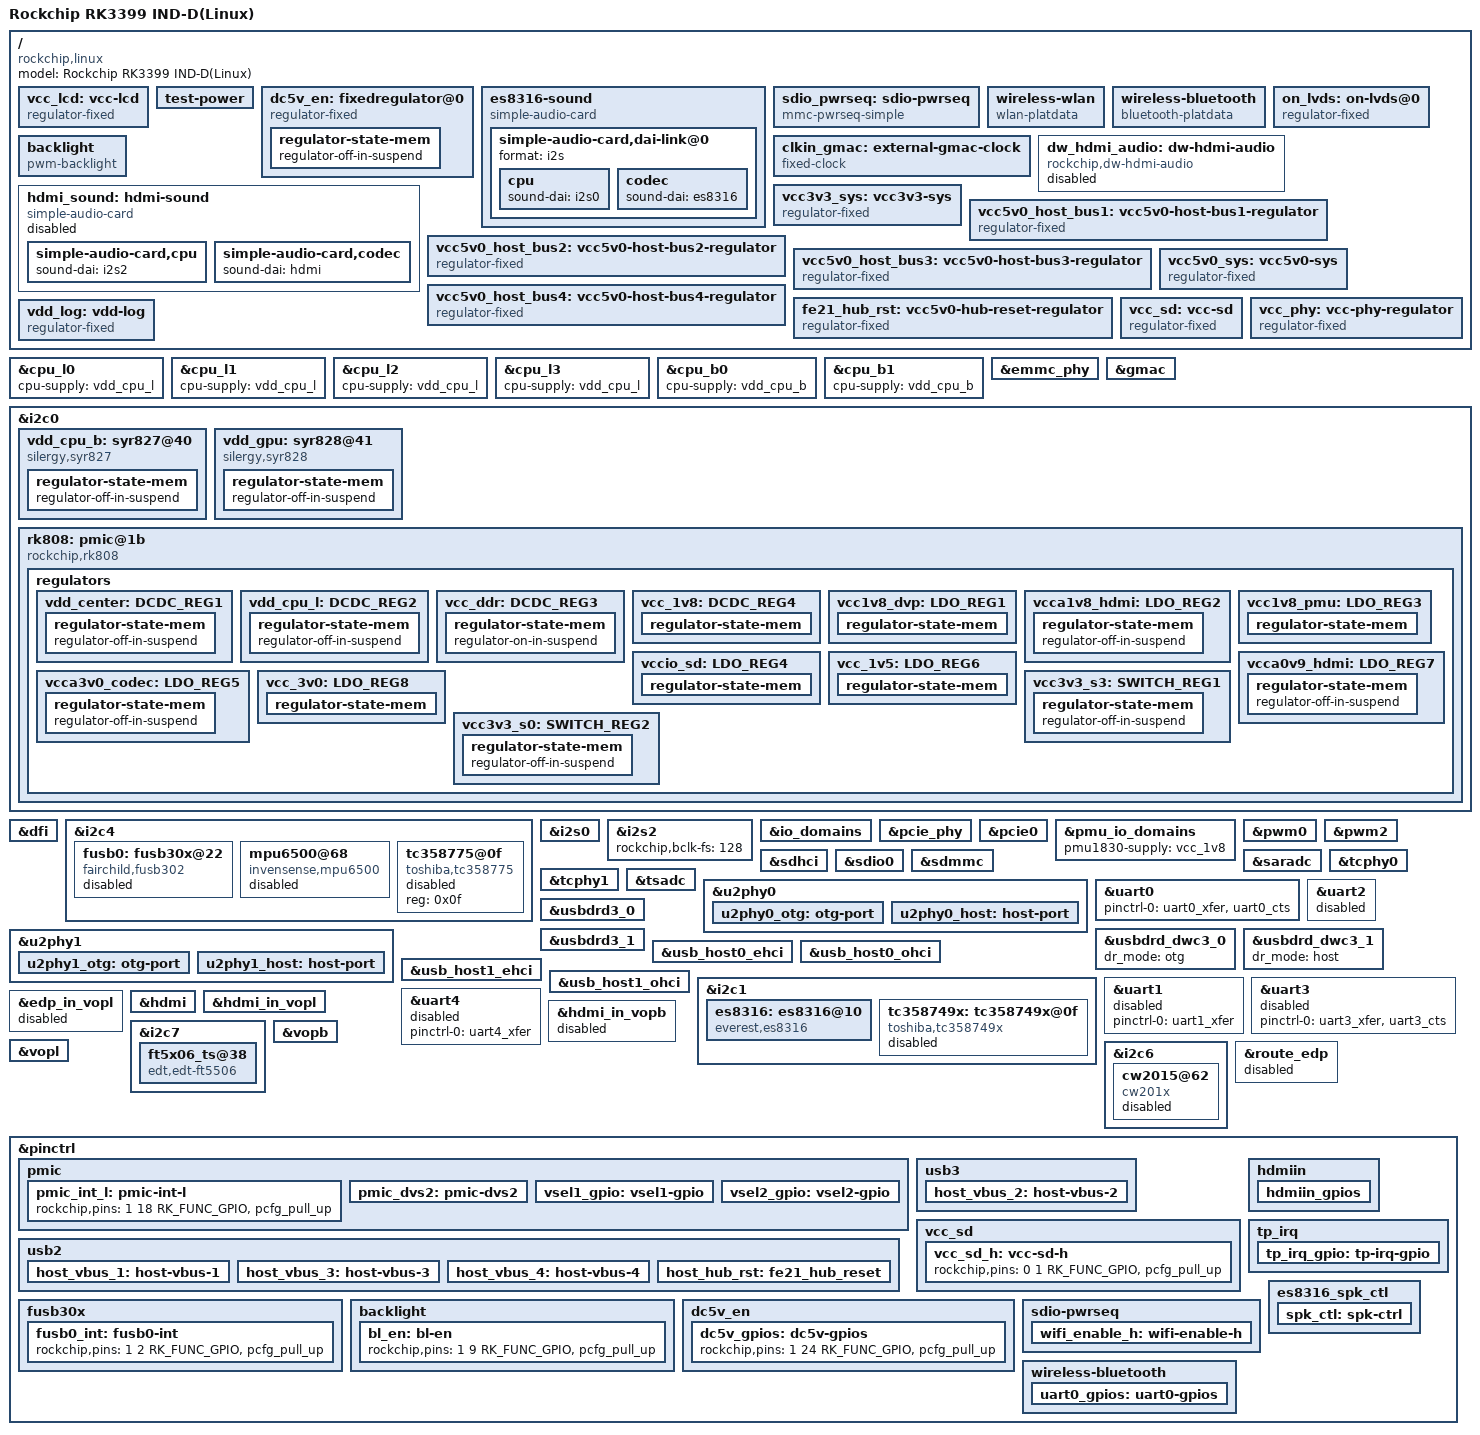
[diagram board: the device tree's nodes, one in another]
/*
 * Copyright (c) 2016 Fuzhou Rockchip Electronics Co., Ltd
 *
 * This file is dual-licensed: you can use it either under the terms
 * of the GPL or the X11 license, at your option. Note that this dual
 * licensing only applies to this file, and not this project as a
 * whole.
 *
 *  a) This file is free software; you can redistribute it and/or
 *     modify it under the terms of the GNU General Public License as
 *     published by the Free Software Foundation; either version 2 of the
 *     License, or (at your option) any later version.
 *
 *     This file is distributed in the hope that it will be useful,
 *     but WITHOUT ANY WARRANTY; without even the implied warranty of
 *     MERCHANTABILITY or FITNESS FOR A PARTICULAR PURPOSE.  See the
 *     GNU General Public License for more details.
 *
 * Or, alternatively,
 *
 *  b) Permission is hereby granted, free of charge, to any person
 *     obtaining a copy of this software and associated documentation
 *     files (the "Software"), to deal in the Software without
 *     restriction, including without limitation the rights to use,
 *     copy, modify, merge, publish, distribute, sublicense, and/or
 *     sell copies of the Software, and to permit persons to whom the
 *     Software is furnished to do so, subject to the following
 *     conditions:
 *
 *     The above copyright notice and this permission notice shall be
 *     included in all copies or substantial portions of the Software.
 *
 *     THE SOFTWARE IS PROVIDED "AS IS", WITHOUT WARRANTY OF ANY KIND,
 *     EXPRESS OR IMPLIED, INCLUDING BUT NOT LIMITED TO THE WARRANTIES
 *     OF MERCHANTABILITY, FITNESS FOR A PARTICULAR PURPOSE AND
 *     NONINFRINGEMENT. IN NO EVENT SHALL THE AUTHORS OR COPYRIGHT
 *     HOLDERS BE LIABLE FOR ANY CLAIM, DAMAGES OR OTHER LIABILITY,
 *     WHETHER IN AN ACTION OF CONTRACT, TORT OR OTHERWISE, ARISING
 *     FROM, OUT OF OR IN CONNECTION WITH THE SOFTWARE OR THE USE OR
 *     OTHER DEALINGS IN THE SOFTWARE.
 */

/dts-v1/;

//#include "rk3399-ind-linux.dtsi"
//#include "rk3399-vop-clk-set.dtsi"
#include "dt-bindings/pwm/pwm.h"
#include "rk3399.dtsi"
//#include "rk3399-opp.dtsi"
#include <dt-bindings/pinctrl/rockchip.h>
#include "rk3399-sdram-lpddr3-4GB-1600.dtsi"
#include "rk3399-u-boot.dtsi"
#include <dt-bindings/input/input.h>
/ {
	model = "Rockchip RK3399 IND-D(Linux)";
	compatible = "rockchip,linux", "rockchip,rk3399-excavator-edp", "rockchip,rk3399";

	vcc_lcd: vcc-lcd {
		compatible = "regulator-fixed";
		regulator-name = "vcc_lcd";
		gpio = <&gpio4 30 GPIO_ACTIVE_HIGH>;
		startup-delay-us = <20000>;
		enable-active-high;
		regulator-min-microvolt = <3300000>;
		regulator-max-microvolt = <3300000>;
		regulator-boot-on;
		vin-supply = <&vcc5v0_sys>;
	};

	test-power {
		status = "okay";
	};

	dc5v_en:fixedregulator@0 {
		compatible = "regulator-fixed";
		regulator-name = "dc5v_en-supply";
		pinctrl-names = "default";
		pinctrl-0=<&dc5v_gpios>;
		regulator-min-microvolt = <1800000>;
        regulator-max-microvolt = <1800000>;
		gpio  = <&gpio1 24 GPIO_ACTIVE_HIGH>;
		enable-active-high;
		regulator-always-on;
		regulator-boot-on;
		enable-at-boot;
		regulator-initial-state = <3>;
		regulator-state-mem{
		regulator-off-in-suspend;
		};
	};
		
	es8316-sound {
		compatible = "simple-audio-card";
		simple-audio-card,format = "i2s";
		simple-audio-card,name = "rockchip,es8316-codec";
		simple-audio-card,mclk-fs = <256>;
		simple-audio-card,widgets =
			"Microphone", "Mic Jack",
			"Headphone", "Headphone Jack";
		simple-audio-card,routing =
			"Mic Jack", "MICBIAS1",
			"IN1P", "Mic Jack",
			"Headphone Jack", "HPOL",
			"Headphone Jack", "HPOR";
		simple-audio-card,dai-link@0 {
			format = "i2s";
			cpu {
				sound-dai = <&i2s0>;
			};

			codec {
				sound-dai = <&es8316>;
			};
		};
	};
	
	sdio_pwrseq: sdio-pwrseq {
		compatible = "mmc-pwrseq-simple";
		clocks = <&rk808 1>;
		clock-names = "ext_clock";
		pinctrl-names = "default";
		pinctrl-0 = <&wifi_enable_h>;

		/*
		 * On the module itself this is one of these (depending
		 * on the actual card populated):
		 * - SDIO_RESET_L_WL_REG_ON
		 * - PDN (power down when low)
		 */
		reset-gpios = <&gpio0 10 GPIO_ACTIVE_LOW>; /* GPIO0_B2 */
	};

	wireless-wlan {
		compatible = "wlan-platdata";
		rockchip,grf = <&grf>;
		wifi_chip_type = "ap6354";
		sdio_vref = <1800>;
		WIFI,host_wake_irq = <&gpio0 3 GPIO_ACTIVE_HIGH>; /* GPIO0_a3 */
		status = "okay";
	};

	wireless-bluetooth {
		compatible = "bluetooth-platdata";
		clocks = <&rk808 1>;
		clock-names = "ext_clock";
		//wifi-bt-power-toggle;
		uart_rts_gpios = <&gpio2 19 GPIO_ACTIVE_LOW>; /* GPIO2_C3 */
		pinctrl-names = "default", "rts_gpio";
		pinctrl-0 = <&uart0_rts>;
		pinctrl-1 = <&uart0_gpios>;
		//BT,power_gpio  = <&gpio3 19 GPIO_ACTIVE_HIGH>; /* GPIOx_xx */
		BT,reset_gpio    = <&gpio0 9 GPIO_ACTIVE_HIGH>; /* GPIO0_B1 */
		BT,wake_gpio     = <&gpio2 27 GPIO_ACTIVE_HIGH>; /* GPIO2_D3 */
		BT,wake_host_irq = <&gpio0 4 GPIO_ACTIVE_HIGH>; /* GPIO0_A4 */
		status = "okay";
	};
	
	on_lvds:on-lvds@0 {
		compatible = "regulator-fixed";
		regulator-name = "on_lvds";
		gpio = <&gpio4 3 GPIO_ACTIVE_HIGH>;
		enable-active-high;
		regulator-min-microvolt = <3300000>;
		regulator-max-microvolt = <3300000>;
		regulator-boot-on;
	};

	backlight: backlight {
		status = "okay";
		compatible = "pwm-backlight";
		power-supply = <&on_lvds>;
		pwms = <&pwm0 0 25000 0>;
		brightness-levels = <
			 70 70  71  71  71  72  72  72
			 73  73  73  74  74  74  75  75
			 75  76  76  76  77  77  77  78
			 78  78  79  79  79  80  80  80
			 81  81  82  82  83  83  84  84
			 85  85  86  86  87  87  88  88
			 89  89  90  90  91  91  92  92
			 93  93  94  94  95  95  96  96
			 97  97  98  98  99  99  100  100
			101  101  102  102  103  103  104  104
			105  105  106  106  107  107  108  108
			109  109  110  110  111  111  112  112
			113  113  114  114 115 115 116 116
			117 117 118 118 119 119 120 121
			122 122 123 124 124 125 126 126
			127 128 128 129 130 131 131 132
			133 133 134 135 136 136 137 138
			138 139 140 141 141 142 143 143
			144 145 146 147 148 149 150 151
			152 153 154 155 156 157 158 159
			160 161 162 163 164 165 166 167
			168 169 170 171 172 173 174 175
			176 177 178 179 180 181 182 183
			184 185 186 187 188 189 190 191
			192 193 194 195 196 197 198 199
			200 201 202 203 204 205 206 207
			208 209 210 211 212 213 214 215
			216 217 218 219 220 221 222 223
			224 225 226 227 228 229 230 231
			232 233 234 235 236 237 238 239
			240 241 242 243 244 245 246 247
			248 249 250 251 252 253 254 255
		>;
		default-brightness-level = <200>;
		pinctrl-names = "default";
		pinctrl-0 = <&bl_en>;
		enable-gpios = <&gpio1 9 GPIO_ACTIVE_LOW>;
		enable-delay-ms = <20>;
	};

	clkin_gmac: external-gmac-clock {
		compatible = "fixed-clock";
		clock-frequency = <125000000>;
		clock-output-names = "clkin_gmac";
		#clock-cells = <0>;
	};

	dw_hdmi_audio: dw-hdmi-audio {
		status = "disabled";
		compatible = "rockchip,dw-hdmi-audio";
		#sound-dai-cells = <0>;
	};

	hdmi_sound: hdmi-sound {
		status = "disabled";
		compatible = "simple-audio-card";
		simple-audio-card,format = "i2s";
		simple-audio-card,mclk-fs = <256>;
		simple-audio-card,name = "rockchip,hdmi";

		simple-audio-card,cpu {
			sound-dai = <&i2s2>;
		};
		simple-audio-card,codec {
			sound-dai = <&hdmi>;
		};
	};

	vcc3v3_sys: vcc3v3-sys {
		compatible = "regulator-fixed";
		regulator-name = "vcc3v3_sys";
		regulator-always-on;
		regulator-boot-on;
		regulator-min-microvolt = <3300000>;
		regulator-max-microvolt = <3300000>;
	};

	vcc5v0_host_bus1: vcc5v0-host-bus1-regulator {
		compatible = "regulator-fixed";
		enable-active-high;
		gpio = <&gpio4 28 GPIO_ACTIVE_HIGH>;
		pinctrl-names = "default";
		pinctrl-0 = <&host_vbus_1>;
		regulator-name = "vcc5v0_host_bus1";
		regulator-always-on;
	};
	
	vcc5v0_host_bus2: vcc5v0-host-bus2-regulator {
		compatible = "regulator-fixed";
		enable-active-high;
		gpio = <&gpio4 4 GPIO_ACTIVE_HIGH>;
		pinctrl-names = "default";
		pinctrl-0 = <&host_vbus_2>;
		regulator-name = "vcc5v0_host_bus2";
		regulator-always-on;
	};
	
	vcc5v0_host_bus3: vcc5v0-host-bus3-regulator {
		compatible = "regulator-fixed";
		enable-active-high;
		gpio = <&gpio4 5 GPIO_ACTIVE_HIGH>;
		pinctrl-names = "default";
		pinctrl-0 = <&host_vbus_3>;
		regulator-name = "vcc5v0_host_bus3";
		regulator-always-on;
	};
	
	vcc5v0_host_bus4: vcc5v0-host-bus4-regulator {
		compatible = "regulator-fixed";
		enable-active-high;
		gpio = <&gpio4 6 GPIO_ACTIVE_HIGH>;
		pinctrl-names = "default";
		pinctrl-0 = <&host_vbus_4>;
		regulator-name = "vcc5v0_host_bus4";
		regulator-always-on;
	};

	fe21_hub_rst: vcc5v0-hub-reset-regulator {
		compatible = "regulator-fixed";
		enable-active-high;
		gpio = <&gpio4 21 GPIO_ACTIVE_HIGH>;
		pinctrl-names = "default";
		pinctrl-0 = <&host_hub_rst>;
		regulator-name = "fe21_hub_rst";
		regulator-always-on;
	};

	vcc5v0_sys: vcc5v0-sys {
		compatible = "regulator-fixed";
		regulator-name = "vcc5v0_sys";
		regulator-always-on;
		regulator-boot-on;
		regulator-min-microvolt = <5000000>;
		regulator-max-microvolt = <5000000>;
	};

	vcc_sd: vcc-sd {
		compatible = "regulator-fixed";
		enable-active-high;
		gpio = <&gpio0 1 GPIO_ACTIVE_HIGH>;
		pinctrl-names = "default";
		pinctrl-0 = <&vcc_sd_h>;
		regulator-name = "vcc_sd";
		regulator-min-microvolt = <3300000>;
		regulator-max-microvolt = <3300000>;
	};

	vcc_phy: vcc-phy-regulator {
		compatible = "regulator-fixed";
		regulator-name = "vcc_phy";
		regulator-always-on;
		regulator-boot-on;
	};

	vdd_log: vdd-log {
		//compatible = "pwm-regulator";
		compatible = "regulator-fixed";
		//pwms = <&pwm2 0 25000 1>;
		regulator-name = "vdd_log";
		regulator-min-microvolt = <800000>;
		regulator-max-microvolt = <1400000>;
		regulator-always-on;
		regulator-boot-on;

		/* for rockchip boot on
		rockchip,pwm_id= <2>;
		rockchip,pwm_voltage = <900000>; */
	};
};

&cpu_l0 {
	cpu-supply = <&vdd_cpu_l>;
};

&cpu_l1 {
	cpu-supply = <&vdd_cpu_l>;
};

&cpu_l2 {
	cpu-supply = <&vdd_cpu_l>;
};

&cpu_l3 {
	cpu-supply = <&vdd_cpu_l>;
};

&cpu_b0 {
	cpu-supply = <&vdd_cpu_b>;
};

&cpu_b1 {
	cpu-supply = <&vdd_cpu_b>;
};

&emmc_phy {
	status = "okay";
};

&gmac {
	phy-supply = <&vcc_phy>;
	phy-mode = "rgmii";
	clock_in_out = "input";
	snps,reset-gpio = <&gpio3 15 GPIO_ACTIVE_LOW>;
	snps,reset-active-low;
	snps,reset-delays-us = <0 10000 50000>;
	assigned-clocks = <&cru SCLK_RMII_SRC>;
	assigned-clock-parents = <&clkin_gmac>;
	pinctrl-names = "default";
	pinctrl-0 = <&rgmii_pins>;
	tx_delay = <0x28>;
	rx_delay = <0x11>;
	status = "okay";
};

&i2c0 {
	status = "okay";
	i2c-scl-rising-time-ns = <168>;
	i2c-scl-falling-time-ns = <4>;
	clock-frequency = <400000>;

	vdd_cpu_b: syr827@40 {
		compatible = "silergy,syr827";
		reg = <0x40>;
		vin-supply = <&vcc5v0_sys>;
		regulator-compatible = "fan53555-reg";
		pinctrl-names = "default";
		pinctrl-0 = <&vsel1_gpio>;
		vsel-gpios = <&gpio1 17 GPIO_ACTIVE_HIGH>;
		regulator-name = "vdd_cpu_b";
		regulator-min-microvolt = <712500>;
		regulator-max-microvolt = <1500000>;
		regulator-ramp-delay = <1000>;
		fcs,suspend-voltage-selector = <1>;
		regulator-always-on;
		regulator-boot-on;
		regulator-initial-state = <3>;
			regulator-state-mem {
			regulator-off-in-suspend;
		};
	};

	vdd_gpu: syr828@41 {
		compatible = "silergy,syr828";
		reg = <0x41>;
		vin-supply = <&vcc5v0_sys>;
		regulator-compatible = "fan53555-reg";
		pinctrl-names = "default";
		pinctrl-0 = <&vsel2_gpio>;
		vsel-gpios = <&gpio1 14 GPIO_ACTIVE_HIGH>;
		regulator-name = "vdd_gpu";
		regulator-min-microvolt = <712500>;
		regulator-max-microvolt = <1500000>;
		regulator-ramp-delay = <1000>;
		fcs,suspend-voltage-selector = <1>;
		regulator-always-on;
		regulator-boot-on;
		regulator-initial-state = <3>;
			regulator-state-mem {
			regulator-off-in-suspend;
		};
	};

	rk808: pmic@1b {
		compatible = "rockchip,rk808";
		reg = <0x1b>;
		interrupt-parent = <&gpio1>;
		interrupts = <21 IRQ_TYPE_LEVEL_LOW>;
		pinctrl-names = "default";
		pinctrl-0 = <&pmic_int_l &pmic_dvs2>;
		rockchip,system-power-controller;
		wakeup-source;
		#clock-cells = <1>;
		clock-output-names = "xin32k", "rk808-clkout2";

		vcc1-supply = <&vcc3v3_sys>;
		vcc2-supply = <&vcc3v3_sys>;
		vcc3-supply = <&vcc3v3_sys>;
		vcc4-supply = <&vcc3v3_sys>;
		vcc6-supply = <&vcc3v3_sys>;
		vcc7-supply = <&vcc3v3_sys>;
		vcc8-supply = <&vcc3v3_sys>;
		vcc9-supply = <&vcc3v3_sys>;
		vcc10-supply = <&vcc3v3_sys>;
		vcc11-supply = <&vcc3v3_sys>;
		vcc12-supply = <&vcc3v3_sys>;
		vddio-supply = <&vcc_3v0>;

		regulators {
			vdd_center: DCDC_REG1 {
				regulator-always-on;
				regulator-boot-on;
				regulator-min-microvolt = <750000>;
				regulator-max-microvolt = <1350000>;
				regulator-ramp-delay = <6001>;
				regulator-name = "vdd_center";
				regulator-state-mem {
					regulator-off-in-suspend;
				};
			};

			vdd_cpu_l: DCDC_REG2 {
				regulator-always-on;
				regulator-boot-on;
				regulator-min-microvolt = <750000>;
				regulator-max-microvolt = <1350000>;
				regulator-ramp-delay = <6001>;
				regulator-name = "vdd_cpu_l";
				regulator-state-mem {
					regulator-off-in-suspend;
				};
			};

			vcc_ddr: DCDC_REG3 {
				regulator-always-on;
				regulator-boot-on;
				regulator-name = "vcc_ddr";
				regulator-state-mem {
					regulator-on-in-suspend;
				};
			};

			vcc_1v8: DCDC_REG4 {
				regulator-always-on;
				regulator-boot-on;
				regulator-min-microvolt = <1800000>;
				regulator-max-microvolt = <1800000>;
				regulator-name = "vcc_1v8";
				regulator-state-mem {
					regulator-on-in-suspend;
					regulator-suspend-microvolt = <1800000>;
				};
			};

			vcc1v8_dvp: LDO_REG1 {
				regulator-always-on;
				regulator-boot-on;
				regulator-min-microvolt = <1800000>;
				regulator-max-microvolt = <1800000>;
				regulator-name = "vcc1v8_dvp";
				regulator-state-mem {
					regulator-on-in-suspend;
					regulator-suspend-microvolt = <1800000>;
				};
			};

			vcca1v8_hdmi: LDO_REG2 {
				regulator-always-on;
				regulator-boot-on;
				regulator-min-microvolt = <1800000>;
				regulator-max-microvolt = <1800000>;
				regulator-name = "vcca1v8_hdmi";
				regulator-state-mem {
					regulator-off-in-suspend;
				};
			};

			vcc1v8_pmu: LDO_REG3 {
				regulator-always-on;
				regulator-boot-on;
				regulator-min-microvolt = <1800000>;
				regulator-max-microvolt = <1800000>;
				regulator-name = "vcc1v8_pmu";
				regulator-state-mem {
					regulator-on-in-suspend;
					regulator-suspend-microvolt = <1800000>;
				};
			};

			vccio_sd: LDO_REG4 {
				regulator-always-on;
				regulator-boot-on;
				regulator-min-microvolt = <1800000>;
				regulator-max-microvolt = <3000000>;
				regulator-name = "vccio_sd";
				regulator-state-mem {
					regulator-on-in-suspend;
					regulator-suspend-microvolt = <3000000>;
				};
			};

			vcca3v0_codec: LDO_REG5 {
				regulator-always-on;
				regulator-boot-on;
				regulator-min-microvolt = <3000000>;
				regulator-max-microvolt = <3000000>;
				regulator-name = "vcca3v0_codec";
				regulator-state-mem {
					regulator-off-in-suspend;
				};
			};

			vcc_1v5: LDO_REG6 {
				regulator-always-on;
				regulator-boot-on;
				regulator-min-microvolt = <1500000>;
				regulator-max-microvolt = <1500000>;
				regulator-name = "vcc_1v5";
				regulator-state-mem {
					regulator-on-in-suspend;
					regulator-suspend-microvolt = <1500000>;
				};
			};

			vcca0v9_hdmi: LDO_REG7 {
				regulator-always-on;
				regulator-boot-on;
				regulator-min-microvolt = <900000>;
				regulator-max-microvolt = <900000>;
				regulator-name = "vcca0v9_hdmi";
				regulator-state-mem {
					regulator-off-in-suspend;
				};
			};

			vcc_3v0: LDO_REG8 {
				regulator-always-on;
				regulator-boot-on;
				regulator-min-microvolt = <3000000>;
				regulator-max-microvolt = <3000000>;
				regulator-name = "vcc_3v0";
				regulator-state-mem {
					regulator-on-in-suspend;
					regulator-suspend-microvolt = <3000000>;
				};
			};

			vcc3v3_s3: SWITCH_REG1 {
				regulator-always-on;
				regulator-boot-on;
				regulator-name = "vcc3v3_s3";
				regulator-state-mem {
					regulator-off-in-suspend;
				};
			};

			vcc3v3_s0: SWITCH_REG2 {
				regulator-always-on;
				regulator-boot-on;
				regulator-name = "vcc3v3_s0";
				regulator-state-mem {
					regulator-off-in-suspend;
				};
			};
		};
	};
	
};

&dfi {
	status = "okay";
};

&i2c4 {
	status = "okay";
	i2c-scl-rising-time-ns = <475>;
	i2c-scl-falling-time-ns = <26>;

	fusb0: fusb30x@22 {
		compatible = "fairchild,fusb302";
		reg = <0x22>;
		pinctrl-names = "default";
		pinctrl-0 = <&fusb0_int>;
		int-n-gpios = <&gpio1 2 GPIO_ACTIVE_HIGH>;
		vbus-5v-gpios = <&gpio2 0 GPIO_ACTIVE_HIGH>;
		status = "disabled";
	};
};

&i2s0 {
	status = "okay";
	rockchip,i2s-broken-burst-len;
	rockchip,playback-channels = <8>;
	rockchip,capture-channels = <8>;
	#sound-dai-cells = <0>;
};

&i2s2 {
	#sound-dai-cells = <0>;
	status = "okay";
};

&io_domains {
	status = "okay";

	//bt656-supply = <&vcc_1v8>;		/* bt656_gpio2ab_ms APIO2 not connect*/
	audio-supply = <&vcc1v8_dvp>;	/*VLDO1 */  /* audio_gpio3d4a_ms d:APIO5 1.8V RK808 Buck4*/
	sdmmc-supply = <&vccio_sd>;		/* sdmmc_gpio4b_ms  d:SDMMC0 3.0V RK808 VLDO4*/
	gpio1830-supply = <&vcc_3v0>;		/* gpio1833_gpio4cd_ms d:APIO4 3.0V RK808 VLDO8*/ 
    	bt656-supply = <&vcc_1v8>;	/*APIO3 1.8V RK808 Buck4 */
};

&pcie_phy {
	status = "okay";
};

&pcie0 {
	ep-gpios = <&gpio2 RK_PA4 GPIO_ACTIVE_HIGH>;
	num-lanes = <4>;
	pinctrl-names = "default";
	pinctrl-0 = <&pcie_clkreqn>;
	status = "okay";
};

&pmu_io_domains {
	status = "okay";
	pmu1830-supply = <&vcc_1v8>; /* datasheet pmu1830_gpio1abcd  d:PMUIO2 1.8V RK808 Buck4 */
};

&pwm0 {
	status = "okay";
};

&pwm2 {
	status = "okay";
};

&sdhci {
	bus-width = <8>;
	mmc-hs400-1_8v;
	supports-emmc;
	non-removable;
	keep-power-in-suspend;
	mmc-hs400-enhanced-strobe;
	status = "okay";
};

&sdio0 {
	clock-frequency = <50000000>;
	clock-freq-min-max = <200000 50000000>;
	supports-sdio;
	bus-width = <4>;
	disable-wp;
	cap-sd-highspeed;
	cap-sdio-irq;
	keep-power-in-suspend;
	mmc-pwrseq = <&sdio_pwrseq>;
	non-removable;
	num-slots = <1>;
	pinctrl-names = "default";
	pinctrl-0 = <&sdio0_bus4 &sdio0_cmd &sdio0_clk>;
	sd-uhs-sdr104;
	status = "okay";
};

&sdmmc {
	clock-frequency = <150000000>;
	clock-freq-min-max = <100000 150000000>;
	supports-sd;
	bus-width = <4>;
	cap-mmc-highspeed;
	cap-sd-highspeed;
	disable-wp;
	num-slots = <1>;
	//sd-uhs-sdr104;
	vmmc-supply = <&vcc_sd>;
	vqmmc-supply = <&vccio_sd>;
	pinctrl-names = "default";
	pinctrl-0 = <&sdmmc_clk &sdmmc_cmd &sdmmc_cd &sdmmc_bus4>;
	status = "okay";
};

&saradc {
	status = "okay";
};

&tcphy0 {
	/*extcon = <&fusb0>;*/
	/*extcon = <&u2phy0>;*/
	status = "okay";
};

&tcphy1 {
	status = "okay";
};

&tsadc {
	/* tshut mode 0:CRU 1:GPIO */
	rockchip,hw-tshut-mode = <1>;
	/* tshut polarity 0:LOW 1:HIGH */
	rockchip,hw-tshut-polarity = <1>;
	status = "okay";
};

&u2phy0 {
	status = "okay";
/*	extcon = <&fusb0>;*/
	u2phy0_otg: otg-port {
		status = "okay";
	};

	u2phy0_host: host-port {
		status = "okay";
	};
};

&u2phy1 {
	status = "okay";

	u2phy1_otg: otg-port {
		status = "okay";
	};

	u2phy1_host: host-port {
		status = "okay";
	};
};

&uart0 {
	status = "okay";
};

&uart2 {
	status = "disabled";
};

&usbdrd3_0 {
	status = "okay";
	/* extcon = <&u2phy0>;*/
};

&usbdrd3_1 {
	status = "okay";
};

&usbdrd_dwc3_0 {
	status = "okay";
	dr_mode = "otg";
};

&usbdrd_dwc3_1 {
	status = "okay";
	dr_mode = "host";
};

&usb_host0_ehci {
	status = "okay";
};

&usb_host0_ohci {
	status = "okay";
};

&usb_host1_ehci {
	status = "okay";
};

&usb_host1_ohci {
	status = "okay";
};

&i2c1 {
	status = "okay";
	i2c-scl-rising-time-ns = <140>;
	i2c-scl-falling-time-ns = <30>;

	es8316: es8316@10 {
		#sound-dai-cells = <0>;
		compatible = "everest,es8316";
		reg = <0x10>;
		clocks = <&cru SCLK_I2S_8CH_OUT>;
		clock-names = "mclk";
		pinctrl-names = "default";
		pinctrl-0 = <&spk_ctl>;
		spk-con-gpio = <&gpio4 7 GPIO_ACTIVE_HIGH>;
		//hp-det-gpio = <&gpio1 0 GPIO_ACTIVE_LOW>;
	};
};

&i2c4 {
	status = "okay";
	i2c-scl-rising-time-ns = <600>;
	i2c-scl-falling-time-ns = <20>;

	mpu6500@68 {
		status = "disabled";
		compatible = "invensense,mpu6500";
		reg = <0x68>;
		irq-gpio = <&gpio1 22 IRQ_TYPE_EDGE_RISING>;
		mpu-int_config = <0x10>;
		mpu-level_shifter = <0>;
		mpu-orientation = <0 1 0 1 0 0 0 0 1>;
		orientation-x= <1>;
		orientation-y= <0>;
		orientation-z= <0>;
		mpu-debug = <1>;
	};
	
	tc358775@0f {
		compatible = "toshiba,tc358775";
		reg = <0x0f>;
		status = "disabled";
	};
};

&uart0 {
	pinctrl-names = "default";
	pinctrl-0 = <&uart0_xfer &uart0_cts>;
	status = "okay";
};

&uart1 {
	pinctrl-names = "default";
	pinctrl-0 = <&uart1_xfer>;
	status = "disabled";
};

&uart3 {
	pinctrl-names = "default";
	pinctrl-0 = <&uart3_xfer &uart3_cts>;
	status = "disabled";
};

&uart4 {
	pinctrl-names = "default";
	pinctrl-0 = <&uart4_xfer>;
	status = "disabled";
};

&saradc {
	status = "okay";
};

&edp_in_vopl {
	status = "disabled";
};

&hdmi {
	status = "okay";
};

&hdmi_in_vopl {
	status = "okay";
};

&hdmi_in_vopb {
	status = "disabled";
};

&backlight {
	status = "okay";
};

&i2s2 {
	status = "okay";
};

&i2c1 {
	status = "okay";

	tc358749x: tc358749x@0f {
		compatible = "toshiba,tc358749x";
		reg = <0x0f>;
		power-gpios = <&gpio2 6 GPIO_ACTIVE_HIGH>;
		power18-gpios = <&gpio2 9 GPIO_ACTIVE_HIGH>;
		power33-gpios = <&gpio2 5 GPIO_ACTIVE_HIGH>;
		csi-ctl-gpios = <&gpio2 10 GPIO_ACTIVE_HIGH>;
		stanby-gpios = <&gpio2 8 GPIO_ACTIVE_HIGH>;
		reset-gpios = <&gpio2 7 GPIO_ACTIVE_HIGH>;
		int-gpios = <&gpio2 12 GPIO_ACTIVE_HIGH>;
		pinctrl-names = "default";
		pinctrl-0 = <&hdmiin_gpios>;
		status = "disabled";
	};
};

&i2c7 {
	status = "okay";
	ft5x06_ts@38 {
		status = "okay";
		compatible = "edt,edt-ft5506";
		reg = <0x38>;
		pinctrl-names = "default";
		interrupt-parent = <&gpio0>;
		interrupts = <8 IRQ_TYPE_EDGE_FALLING>;
		wake-gpios = <&gpio0 8 IRQ_TYPE_LEVEL_LOW>;
		reset-gpios = <&gpio3 RK_PA0 GPIO_ACTIVE_HIGH>;
		max-x = <1280>;
		max-y = <800>;
		//tp-size = <101>;
	};
};

&i2c6 {
	cw2015@62 {
		status = "disabled";
		compatible = "cw201x";
		reg = <0x62>;
		bat_config_info = <0x15 0x42 0x60 0x59 0x52 0x58 0x4D 0x48
				   0x48 0x44 0x44 0x46 0x49 0x48 0x32 0x24
				   0x20 0x17 0x13 0x0F 0x19 0x3E 0x51 0x45
				   0x08 0x76 0x0B 0x85 0x0E 0x1C 0x2E 0x3E
				   0x4D 0x52 0x52 0x57 0x3D 0x1B 0x6A 0x2D
				   0x25 0x43 0x52 0x87 0x8F 0x91 0x94 0x52
				   0x82 0x8C 0x92 0x96 0xFF 0x7B 0xBB 0xCB
				   0x2F 0x7D 0x72 0xA5 0xB5 0xC1 0x46 0xAE>;
		monitor_sec = <5>;
		virtual_power = <0>;
	};
};

&i2s2 {
	#sound-dai-cells = <0>;
	rockchip,bclk-fs = <128>;
};

&vopb {
	status = "okay";
	assigned-clocks = <&cru DCLK_VOP0_DIV>;
	assigned-clock-parents = <&cru PLL_CPLL>;
};

&vopl {
	status = "okay";
	assigned-clocks = <&cru DCLK_VOP1_DIV>;
	assigned-clock-parents = <&cru PLL_VPLL>;
};

&pcie_phy {
	status = "okay";
};

&pcie0 {
	status = "okay";
};

&route_edp {
	status = "disabled";
};

&pinctrl {

	pmic {
		pmic_int_l: pmic-int-l {
			rockchip,pins =
				<1 18 RK_FUNC_GPIO &pcfg_pull_up>;
		};
/* tmp config no use pin */
		pmic_dvs2: pmic-dvs2 {
			rockchip,pins =
				<2 0 RK_FUNC_GPIO &pcfg_pull_down>;
		};
		vsel1_gpio: vsel1-gpio {
			rockchip,pins =
				<1 17 RK_FUNC_GPIO &pcfg_pull_down>;
		};
		vsel2_gpio: vsel2-gpio {
			rockchip,pins =
				<1 14 RK_FUNC_GPIO &pcfg_pull_down>;
		};
	};

	usb2 {

		host_vbus_1: host-vbus-1 {
			rockchip,pins =
				<4 28 RK_FUNC_GPIO &pcfg_pull_none>;
		};
		
		host_vbus_3: host-vbus-3 {
			rockchip,pins =
				<4 5 RK_FUNC_GPIO &pcfg_pull_none>;
		};
		
		host_vbus_4: host-vbus-4 {
			rockchip,pins =
				<4 6 RK_FUNC_GPIO &pcfg_pull_none>;
		};
		/*
		host_vbus_5: host-vbus-5 {
			rockchip,pins =
				<4 7 RK_FUNC_GPIO &pcfg_pull_none>;
		};*/

		host_hub_rst: fe21_hub_reset {
			rockchip,pins =
				<4 21 RK_FUNC_GPIO &pcfg_pull_none>;
		};
	};
	
	usb3 {
	/*	host_vbus_drv: host-vbus-drv {
			rockchip,pins =
				<3 30 RK_FUNC_GPIO &pcfg_pull_none>;
		};*/
		
		host_vbus_2: host-vbus-2 {
			rockchip,pins =
				<4 4 RK_FUNC_GPIO &pcfg_pull_none>;
		};
	};

	vcc_sd {
		vcc_sd_h: vcc-sd-h {
			rockchip,pins =
				<0 1 RK_FUNC_GPIO &pcfg_pull_up>;
		};
	};

	fusb30x {
		fusb0_int: fusb0-int {
			rockchip,pins = <1 2 RK_FUNC_GPIO &pcfg_pull_up>;
		};
	};

	backlight { 
		bl_en: bl-en{
			rockchip,pins =
			<1 9 RK_FUNC_GPIO &pcfg_pull_up>;
		};
	};

	hdmiin {
		hdmiin_gpios: hdmiin_gpios {
		rockchip,pins =
				<2 5 RK_FUNC_GPIO &pcfg_pull_none>,
				<2 6 RK_FUNC_GPIO &pcfg_pull_none>,
				<2 7 RK_FUNC_GPIO &pcfg_pull_none>,
				<2 8 RK_FUNC_GPIO &pcfg_pull_none>,
				<2 9 RK_FUNC_GPIO &pcfg_pull_none>,
				<2 12 RK_FUNC_GPIO &pcfg_pull_none>;
		};
	};

	tp_irq {
		tp_irq_gpio: tp-irq-gpio {
			rockchip,pins = <3 RK_PB0 RK_FUNC_GPIO &pcfg_pull_up>;
		};
	};

	dc5v_en {
		dc5v_gpios: dc5v-gpios {
			rockchip,pins =
				<1 24 RK_FUNC_GPIO &pcfg_pull_up>;
		};
	};
	
	sdio-pwrseq {
		wifi_enable_h: wifi-enable-h {
			rockchip,pins =
				<0 10 RK_FUNC_GPIO &pcfg_pull_none>;
		};
	};

	wireless-bluetooth {
		uart0_gpios: uart0-gpios {
			rockchip,pins =
				<2 19 RK_FUNC_GPIO &pcfg_pull_none>;
		};
	};

	es8316_spk_ctl {
		spk_ctl: spk-ctrl {
			rockchip,pins =
				<4 7 RK_FUNC_GPIO &pcfg_pull_none>;
		};
	};
};
